# GD32A72_A74x register map
File version: 1.0
CPU: CM7 r2p1, little endian, MPU, FPU, DSP, 4 interrupt priority bits
Registers are 32-bit, read-write, reset 0x0 unless marked. A register's access mark holds for its fields unless they carry their own. Offsets are from the block's base; [hi:lo] are bit positions; {n}, {i} and the like mark numbered series; 'fields as' and 'values as' point back to an identical list.

## SYSCFG — System and memory architecture
Base 0x40010000
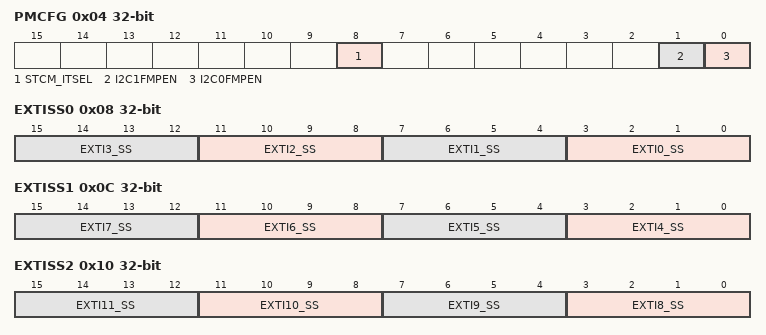
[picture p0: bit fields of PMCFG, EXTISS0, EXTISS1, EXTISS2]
0x04 PMCFG — Peripheral mode configuration register
  [8] STCM_ITSEL — STCM server interface selection
  [1] I2C1FMPEN — I2C1 Fm+
  [0] I2C0FMPEN — I2C0 Fm+
0x08 EXTISS0 — EXTI sources selection register 0
  [4n+3:4n] EXTI{n}_SS (n=0..3) — EXTI {n} sources selection
0x0C EXTISS1 — EXTI sources selection register 1
  [4n-13:4n-16] EXTI{n}_SS (n=4..7) — EXTI {n} sources selection
0x10 EXTISS2 — EXTI sources selection register 2
  [4n-29:4n-32] EXTI{n}_SS (n=8..11) — EXTI {n} sources selection
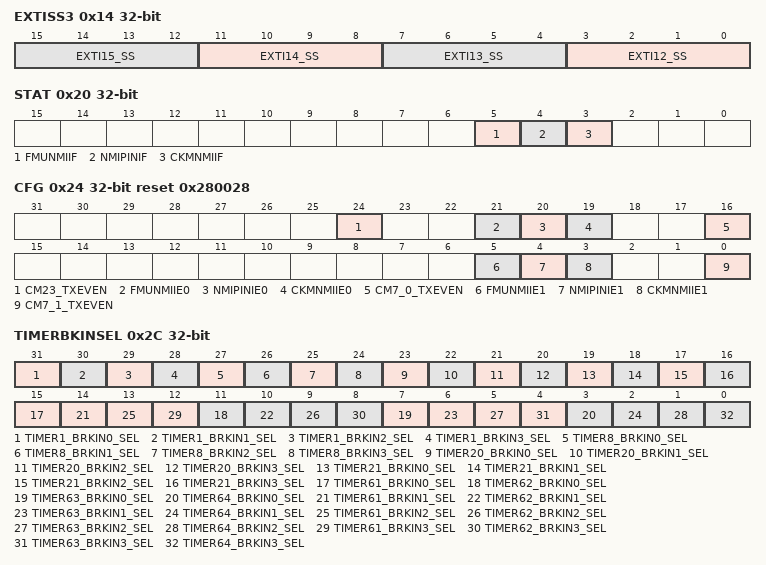
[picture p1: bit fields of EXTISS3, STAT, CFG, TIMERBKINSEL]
0x14 EXTISS3 — EXTI sources selection register 3
  [4n-45:4n-48] EXTI{n}_SS (n=12..15) — EXTI {n} sources selection
0x20 STAT access per field — System status register
  [5] FMUNMIIF ro — NMI interrupt flag from FMU
  [4] NMIPINIF ro — NMI interrupt flag from EXTI pin
  [3] CKMNMIIF rw — HXTAL clock monitor NMI interrupt flag
0x24 CFG reset 0x280028 — System configuration register
  [24] CM23_TXEVEN — This bit can be used to enable the EVENTOUT from CM23
  [21] FMUNMIIE0 — This bit can be used to enable the interrupt flag from FMU connection to CPU0 NMI interrupt
  [20] NMIPINIE0 — This bit can be used to enable the interrupt flag from EXTI connection to CPU0 NMI interrupt
  [19] CKMNMIIE0 — This bit can be used to enable the HXTAL clock monitor NMI interrupt flag connection to CPU0 NMI interrupt
  [16] CM7_0_TXEVEN — This bit can be used to enable the EVENTOUT from CM7_0
  [5] FMUNMIIE1 — This bit can be used to enable the interrupt flag from FMU connection to CPU1 NMI interrupt
  [4] NMIPINIE1 — This bit can be used to enable the interrupt flag from EXTI connection to CPU1 NMI interrupt
  [3] CKMNMIIE1 — This bit can be used to enable the HXTAL clock monitor NMI interrupt flag connection to CPU1 NMI interrupt
  [0] CM7_1_TXEVEN — This bit can be used to enable the EVENTOUT from CM7_1
0x2C TIMERBKINSEL — Timer break input select register
  [31] TIMER1_BRKIN0_SEL — Timer1 break input 3 select
  [30] TIMER1_BRKIN1_SEL — Timer1 break input 2 select
  [29] TIMER1_BRKIN2_SEL — Timer1 break input 1 select
  [28] TIMER1_BRKIN3_SEL — Timer1 break input 0 select
  [27] TIMER8_BRKIN0_SEL — Timer8 break input 3 select
  [26] TIMER8_BRKIN1_SEL — Timer8 break input 2 select
  [25] TIMER8_BRKIN2_SEL — Timer8 break input 1 select
  [24] TIMER8_BRKIN3_SEL — Timer8 break input 0 select
  [23] TIMER20_BRKIN0_SEL — Timer20 break input 3 select
  [22] TIMER20_BRKIN1_SEL — Timer20 break input 2 select
  [21] TIMER20_BRKIN2_SEL — Timer20 break input 1 select
  [20] TIMER20_BRKIN3_SEL — Timer20 break input 0 select
  [19] TIMER21_BRKIN0_SEL — Timer21 break input 3 select
  [18] TIMER21_BRKIN1_SEL — Timer21 break input 2 select
  [17] TIMER21_BRKIN2_SEL — Timer21 break input 1 select
  [16] TIMER21_BRKIN3_SEL — Timer21 break input 0 select
  [259-4n] TIMER{n}_BRKIN0_SEL (n=61..64) — Timer{n} break input 3 select
  [258-4n] TIMER{n}_BRKIN1_SEL (n=61..64) — Timer{n} break input 2 select
  [257-4n] TIMER{n}_BRKIN2_SEL (n=61..64) — Timer{n} break input 1 select
  [256-4n] TIMER{n}_BRKIN3_SEL (n=61..64) — Timer{n} break input 0 select
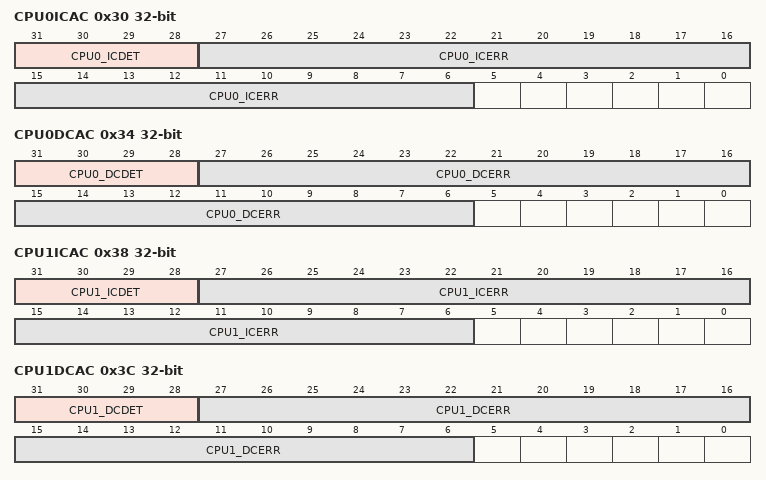
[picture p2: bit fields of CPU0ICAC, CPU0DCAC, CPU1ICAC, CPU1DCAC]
0x30 CPU0ICAC ro — CPU0 ICACHE error status register
  [31:28] CPU0_ICDET — The icache error detection information
  [27:6] CPU0_ICERR — The icache error bank information
0x34 CPU0DCAC ro — CPU0 DCACHE error status register
  [31:28] CPU0_DCDET — The dcache error detection information
  [27:6] CPU0_DCERR — The dcache error bank information
0x38 CPU1ICAC ro — CPU1 ICACHE error status register
  [31:28] CPU1_ICDET — The icache error detection information
  [27:6] CPU1_ICERR — The icache error bank information
0x3C CPU1DCAC ro — CPU1 DCACHE error status register
  [31:28] CPU1_DCDET — The dcache error detection information
  [27:6] CPU1_DCERR — The dcache error bank information
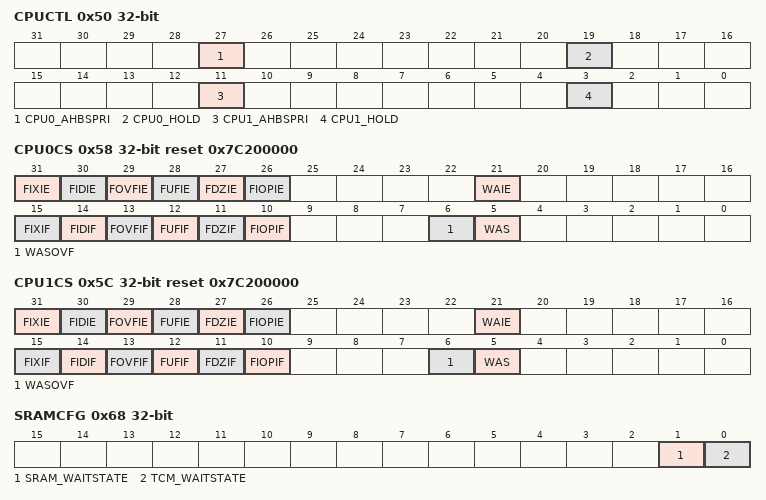
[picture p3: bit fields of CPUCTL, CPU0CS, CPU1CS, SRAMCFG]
0x50 CPUCTL — CPU control register
  [27] CPU0_AHBSPRI — AHB slave port priority of the CM7_0
  [19] CPU0_HOLD — CPU0 hold released
  [11] CPU1_AHBSPRI — AHB slave priority of the CM7_1
  [3] CPU1_HOLD — CPU1 hold released
0x54 CPUSTAT — CPU platform status register
  [1:0] CPUSTAT — CPU information for the chip
0x58 CPU0CS access per field reset 0x7C200000 — CPU0 control and status register
  [31] FIXIE rw — FPU inexact interrupt enable
  [30] FIDIE rw — FPU input denormal interrupt enable
  [29] FOVFIE rw — FPU overflow interrupt enable
  [28] FUFIE rw — FPU underflow interrupt enable
  [27] FDZIE rw — FPU divide-by-zero interrupt enable
  [26] FIOPIE rw — FPU invalid operation interrupt enable
  [21] WAIE rw — TCM write abort interrupt enable
  [15] FIXIF ro — FPU inexact interrupt flag status
  [14] FIDIF ro — FPU input denormal interrupt flag status
  [13] FOVFIF ro — FPU overflow interrupt flag status
  [12] FUFIF ro — FPU underflow interrupt flag status
  [11] FDZIF ro — FPU divide-by-zero interrupt flag status
  [10] FIOPIF ro — FPU invalid operation interrupt flag status
  [6] WASOVF ro — Write abort on slave overrun flag
  [5] WAS rw — Write abort on AHB slave
0x5C CPU1CS access per field reset 0x7C200000 — CPU1 control and status register
  fields as CPU0CS
0x68 SRAMCFG — SRAM configuration register
  [1] SRAM_WAITSTATE — This bit is set and cleared by software
  [0] TCM_WAITSTATE — This bit is set and cleared by software
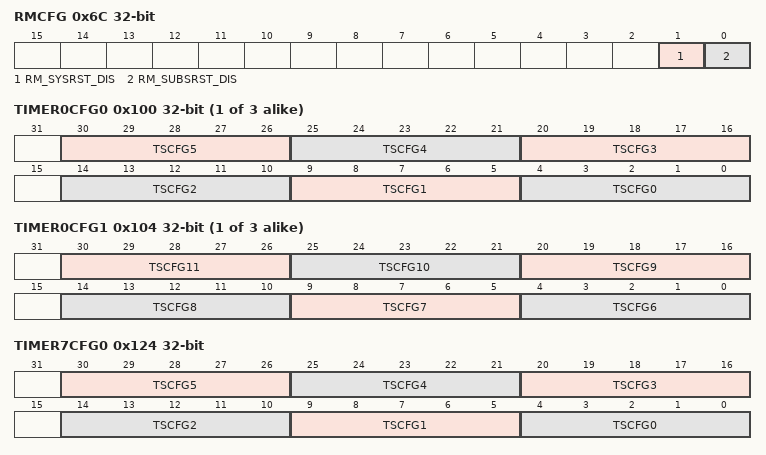
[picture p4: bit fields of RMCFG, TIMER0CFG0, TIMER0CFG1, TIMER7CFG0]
0x6C RMCFG — Recovery mode configuration register
  [1] RM_SYSRST_DIS — Disable recovery mode on system reset
  [0] RM_SUBSRST_DIS — Disable recovery mode on subsystem reset
0x70 HSMSTAT — HSM sub system status register
  [0] HSM_ENTER_STDBY — Indicates that the HSM sub system has entered standby separately
{0x100+0xC*i} TIMER{i}CFG0 (i=0..2) — TIMER{i} configuration register 0
  [30:26] TSCFG5 — Event mode configuration
  [25:21] TSCFG4 — Pause mode configuration
  [20:16] TSCFG3 — Restart mode configuration
  [14:10] TSCFG2 — Quadrature decoder mode 2 configuration
  [9:5] TSCFG1 — Quadrature decoder mode 1 configuration
  [4:0] TSCFG0 — Quadrature decoder mode 0 configuration
{0x104+0xC*i} TIMER{i}CFG1 (i=0..2) — TIMER{i} configuration register 1
  [30:26] TSCFG11 — Non-quadrature decoder mode 3 configuration
  [25:21] TSCFG10 — Non-quadrature decoder mode 2 configuration
  [20:16] TSCFG9 — Non-quadrature decoder mode 1 configuration
  [14:10] TSCFG8 — Non-quadrature decoder mode 0 configuration
  [9:5] TSCFG7 — Restart + event mode configuration
  [4:0] TSCFG6 — External clock mode 0 configuration
{0x108+0xC*i} TIMER{i}CFG2 (i=0..2) — TIMER{i} configuration register 2
  [20:16] TSCFG15 — Internal trigger input source configuration
0x124 TIMER7CFG0 — TIMER7 configuration register 0
  fields as TIMER0CFG0
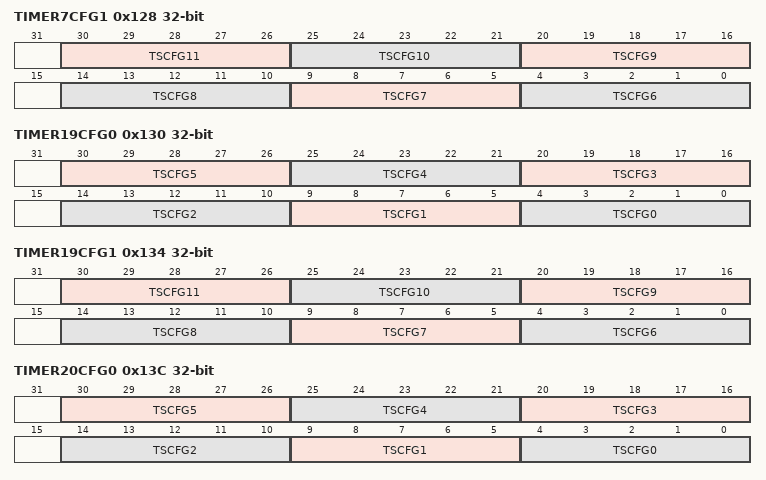
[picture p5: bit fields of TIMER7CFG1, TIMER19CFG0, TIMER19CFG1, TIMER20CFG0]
0x128 TIMER7CFG1 — TIMER7 configuration register 1
  fields as TIMER0CFG1
0x12C TIMER7CFG2 — TIMER7 configuration register 2
  [20:16] TSCFG15 — Internal trigger input source configuration
0x130 TIMER19CFG0 — TIMER19 configuration register 0
  fields as TIMER0CFG0
0x134 TIMER19CFG1 — TIMER19 configuration register 1
  fields as TIMER0CFG1
0x138 TIMER19CFG2 — TIMER19 configuration register 2
  [20:16] TSCFG15 — Internal trigger input source configuration
0x13C TIMER20CFG0 — TIMER20 configuration register 0
  fields as TIMER0CFG0
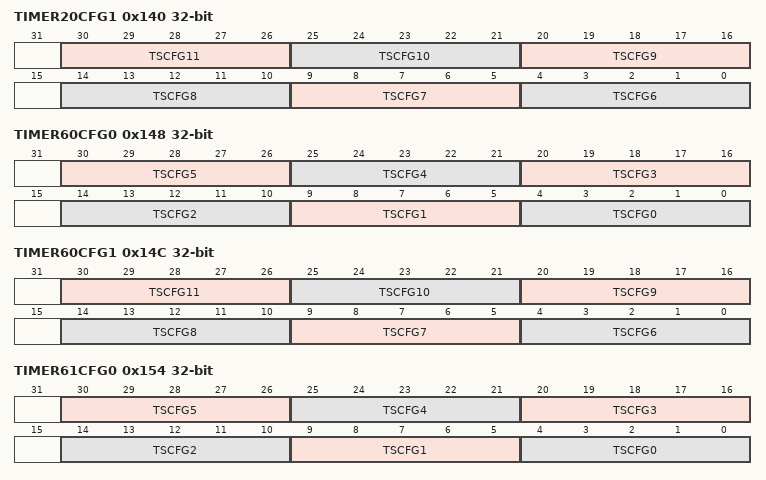
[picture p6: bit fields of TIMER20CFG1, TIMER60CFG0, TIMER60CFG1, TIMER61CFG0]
0x140 TIMER20CFG1 — TIMER20 configuration register 1
  fields as TIMER0CFG1
0x144 TIMER20CFG2 — TIMER20 configuration register 2
  [20:16] TSCFG15 — Internal trigger input source configuration
0x148 TIMER60CFG0 — TIMER60 configuration register 0
  fields as TIMER0CFG0
0x14C TIMER60CFG1 — TIMER60 configuration register 1
  fields as TIMER0CFG1
0x150 TIMER60CFG2 — TIMER60 configuration register 2
  [20:16] TSCFG15 — Internal trigger input source configuration
0x154 TIMER61CFG0 — TIMER61 configuration register 0
  fields as TIMER0CFG0
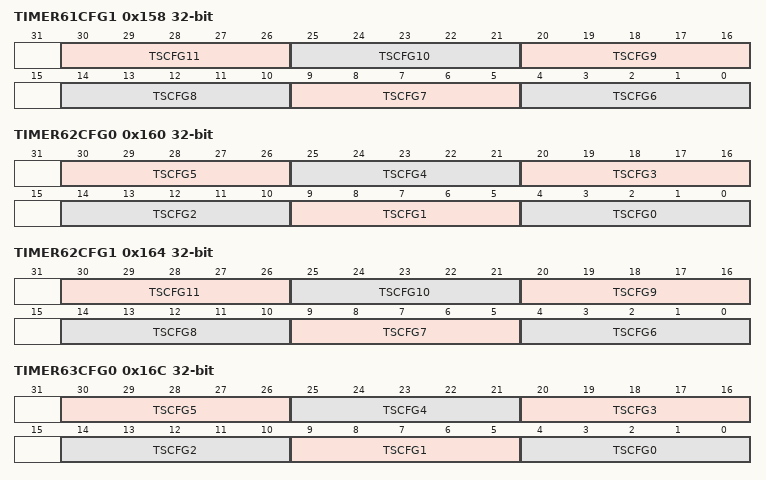
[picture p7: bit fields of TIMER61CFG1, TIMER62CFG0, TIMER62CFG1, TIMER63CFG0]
0x158 TIMER61CFG1 — TIMER61 configuration register 1
  fields as TIMER0CFG1
0x15C TIMER61CFG2 — TIMER61 configuration register 2
  [20:16] TSCFG15 — Internal trigger input source configuration
0x160 TIMER62CFG0 — TIMER62 configuration register 0
  fields as TIMER0CFG0
0x164 TIMER62CFG1 — TIMER62 configuration register 1
  fields as TIMER0CFG1
0x168 TIMER62CFG2 — TIMER62 configuration register 2
  [20:16] TSCFG15 — Internal trigger input source configuration
0x16C TIMER63CFG0 — TIMER63 configuration register 0
  fields as TIMER0CFG0
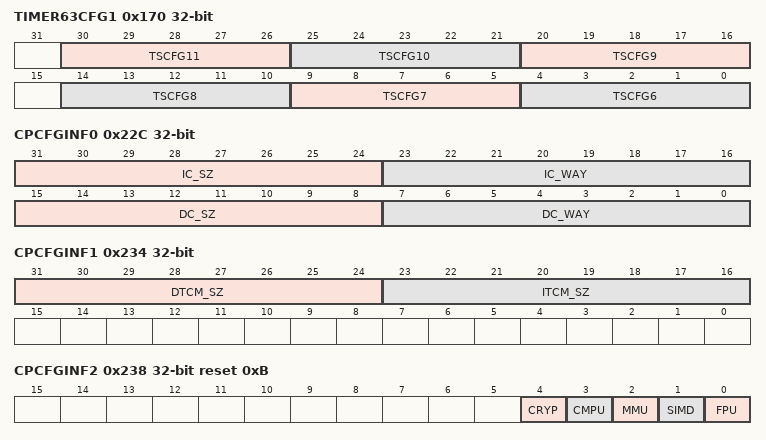
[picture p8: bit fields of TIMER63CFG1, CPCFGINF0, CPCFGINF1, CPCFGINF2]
0x170 TIMER63CFG1 — TIMER63 configuration register 1
  fields as TIMER0CFG1
0x174 TIMER63CFG2 — TIMER63 configuration register 2
  [20:16] TSCFG15 — Internal trigger input source configuration
0x220 CPID ro — Core processor ID register
  [31:0] CPID — Core processor ID
0x224 CPNUM ro — Core porcessor number register
  [1:0] CPNUM — CPU core number
0x22C CPCFGINF0 ro — Core processor configuration information register 0
  [31:24] IC_SZ — L1 instruction cache size
  [23:16] IC_WAY — L1 instruction cache ways
  [15:8] DC_SZ — L1 data cache size
  [7:0] DC_WAY — L1 data cache ways
0x234 CPCFGINF1 ro — Core processor configuration information register 1
  [31:24] DTCM_SZ — DTCM memory size
  [23:16] ITCM_SZ — ITCM memory size
0x238 CPCFGINF2 ro reset 0xB — Core processor configuration information register 2
  [4] CRYP — Cryptography support
  [3] CMPU — Core memory protection unit support
  [2] MMU — Memory management unit support
  [1] SIMD — SIMD/NEON instruction support
  [0] FPU — Floating point unit support
0x240 CP0ID ro reset 0x434D3730 — Core processor 0 ID register
  [31:0] CPID — Core processor ID
0x244 CP0NUM ro — Core processor 0 number register
  [1:0] CPNUM — CPU core number
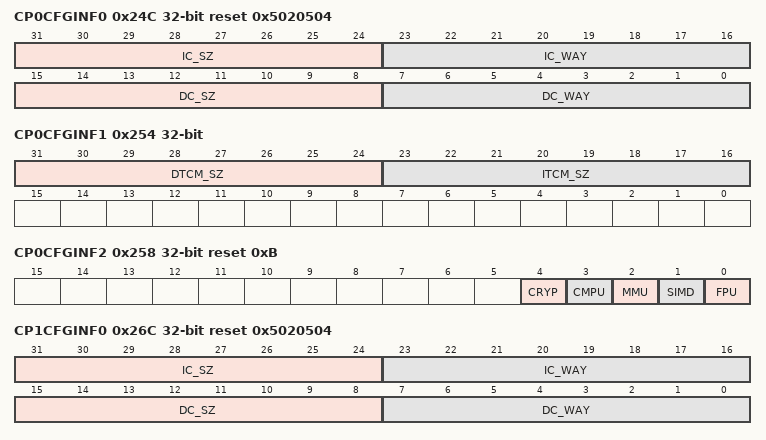
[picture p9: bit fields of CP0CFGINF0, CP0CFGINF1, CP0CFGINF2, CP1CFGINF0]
0x24C CP0CFGINF0 ro reset 0x5020504 — Core processor 0 configuration information register 0
  fields as CPCFGINF0
0x254 CP0CFGINF1 ro — Core processor 0 configuration information register 1
  fields as CPCFGINF1
0x258 CP0CFGINF2 ro reset 0xB — Core processor 0 configuration information register 2
  fields as CPCFGINF2
0x260 CP1ID ro reset 0x434D3731 — Core processor 1 ID register
  [31:0] CPID — Core processor ID
0x264 CP1NUM ro reset 0x1 — Core processor 1 number register
  [1:0] CPNUM — CPU core number
0x26C CP1CFGINF0 ro reset 0x5020504 — Core processor 1 configuration information register 0
  fields as CPCFGINF0
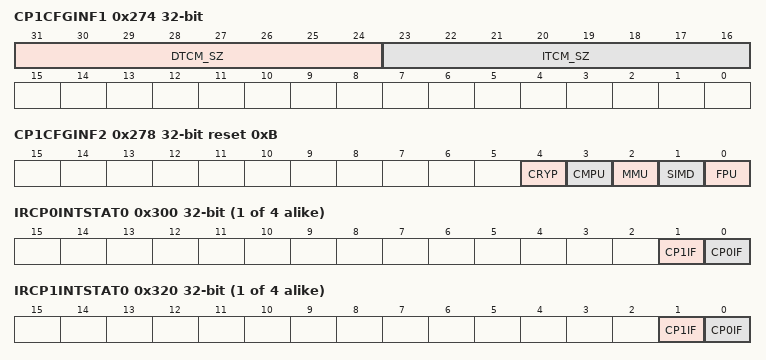
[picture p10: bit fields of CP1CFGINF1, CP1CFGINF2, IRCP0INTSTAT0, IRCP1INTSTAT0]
0x274 CP1CFGINF1 ro — Core processor 1 configuration information register 1
  fields as CPCFGINF1
0x278 CP1CFGINF2 ro reset 0xB — Core processor 1 configuration information register 2
  fields as CPCFGINF2
{0x300+8i} IRCP0INTSTAT{i} (i=0..3) — Interrupt router core processor 0 interrupt status register x
  [1] CP1IF — CP1 to CP0 interrupt flag
  [0] CP0IF — CP0 to CP0 interrupt flag
{0x304+8i} IRCP0INT{i} wo (i=0..3) — Interrupt router core processor 0 interrupt register x
  [0] CPIE — Interrupt enable
{0x320+8i} IRCP1INTSTAT{i} (i=0..3) — Interrupt router core processor 1 interrupt status register x
  [1] CP1IF — CP1-to-CP1 interrupt flag
  [0] CP0IF — CP0-to-CP1 interrupt flag
{0x324+8i} IRCP1INT{i} wo (i=0..3) — Interrupt router core processor 1 interrupt register x
  [0] CPIE — Interrupt enable
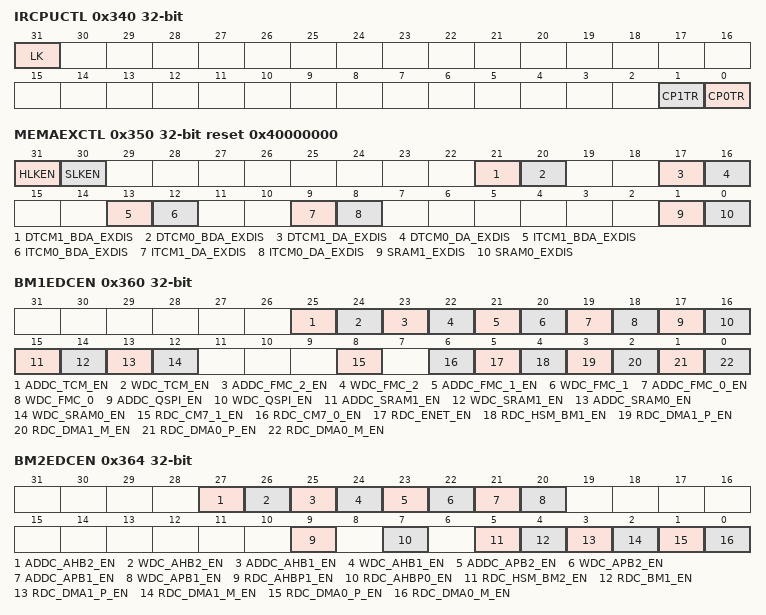
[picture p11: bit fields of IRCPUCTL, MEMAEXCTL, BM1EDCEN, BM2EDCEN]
0x340 IRCPUCTL — Interrupt router core processor control register
  [31] LK — Lock bit
  [1] CP1TR — CP1 configured as trusted core
  [0] CP0TR — CP0 configured as trusted core
0x350 MEMAEXCTL reset 0x40000000 — Memory access execution control registerDTCM0_ DA_EXDIS
  [31] HLKEN — Hard lock enable
  [30] SLKEN — Soft lock enable
  [21] DTCM1_BDA_EXDIS — DTCM core 1 backdoor access execution control
  [20] DTCM0_BDA_EXDIS — DTCM core 0 backdoor access execution control
  [17] DTCM1_DA_EXDIS — DTCM core 1 direct access execution control
  [16] DTCM0_DA_EXDIS — DTCM core 0 direct access execution control
  [13] ITCM1_BDA_EXDIS — ITCM core 1 backdoor access execution control
  [12] ITCM0_BDA_EXDIS — ITCM core 0 backdoor access execution control
  [9] ITCM1_DA_EXDIS — ITCM core 1 direct access execution control
  [8] ITCM0_DA_EXDIS — ITCM core 0 direct access execution control
  [1] SRAM1_EXDIS — SRAM 1 controller access execution control
  [0] SRAM0_EXDIS — SRAM 0 controller access execution control
0x360 BM1EDCEN — Bus matrix 1 interconnect error detection enable register
  [25] ADDC_TCM_EN — Address check TCM SRAM enable
  [24] WDC_TCM_EN — Write data check TCM SRAM enable
  [23] ADDC_FMC_2_EN — Enable address check FMC_2
  [22] WDC_FMC_2 — Enable write data check FMC_2
  [21] ADDC_FMC_1_EN — Enable address check FMC_1
  [20] WDC_FMC_1 — Enable write data check FMC_1
  [19] ADDC_FMC_0_EN — Enable address check FMC_0
  [18] WDC_FMC_0 — Enable write data check FMC_0
  [17] ADDC_QSPI_EN — Enable address check Quad-SPI
  [16] WDC_QSPI_EN — Enable write data check Quad-SPI
  [15] ADDC_SRAM1_EN — Enable address check SRAM1
  [14] WDC_SRAM1_EN — Enable write data check SRAM1
  [13] ADDC_SRAM0_EN — Enable address check SRAM0
  [12] WDC_SRAM0_EN — Enable write data check SRAM0
  [8] RDC_CM7_1_EN — Enable read data check Cortex-M7_1_AXIM
  [6] RDC_CM7_0_EN — Enable read data check Cortex-M7_0_AXIM
  [5] RDC_ENET_EN — Enable read data check ENET
  [4] RDC_HSM_BM1_EN — Enable read data check HSM BM1
  [3] RDC_DMA1_P_EN — Enable read data check DMA1 peripheral accesses
  [2] RDC_DMA1_M_EN — Enable read data check DMA1 memory accesses
  [1] RDC_DMA0_P_EN — Enable read data check DMA0 peripheral accesses
  [0] RDC_DMA0_M_EN — Enable read data check DMA0 memory accesses
0x364 BM2EDCEN — Bus matrix 2 interconnect error detection enable register
  [27] ADDC_AHB2_EN — Enable address check AHB2
  [26] WDC_AHB2_EN — Enable write data check AHB2
  [25] ADDC_AHB1_EN — Enable address check AHB1
  [24] WDC_AHB1_EN — Enable write data check AHB1
  [23] ADDC_APB2_EN — Enable address check APB2
  [22] WDC_APB2_EN — Enable write data check APB2
  [21] ADDC_APB1_EN — Enable address check APB1
  [20] WDC_APB1_EN — Enable write data check APB1
  [9] RDC_AHBP1_EN — Enable read data check Cortex-M7_1_AHBP
  [7] RDC_AHBP0_EN — Enable read data check Cortex-M7_0_AHBP
  [5] RDC_HSM_BM2_EN — Enable read data check HSM BM2
  [4] RDC_BM1_EN — Enable read data check Bus Matrix2 to Bus Matrix1
  [3] RDC_DMA1_P_EN — Enable read data check DMA1 peripheral accesses
  [2] RDC_DMA1_M_EN — Enable read data check DMA1 memory accesses
  [1] RDC_DMA0_P_EN — Enable read data check DMA0 peripheral accesses
  [0] RDC_DMA0_M_EN — Enable read data check DMA0 memory accesses
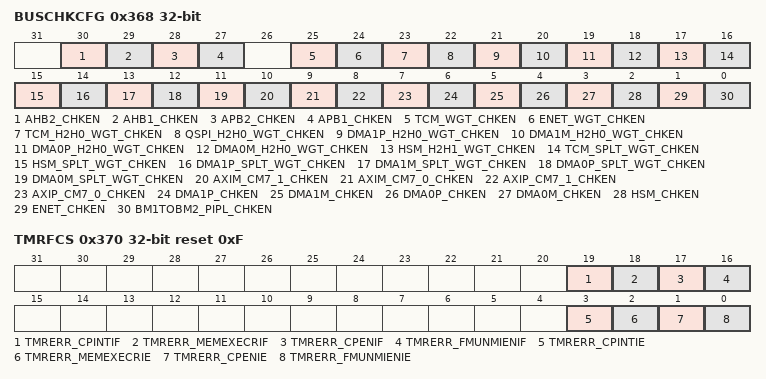
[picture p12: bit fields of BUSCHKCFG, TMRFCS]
0x368 BUSCHKCFG — Bus check configuration register
  [30] AHB2_CHKEN — Enable or disable AHB2 redundant check
  [29] AHB1_CHKEN — Enable or disable AHB1 redundant check
  [28] APB2_CHKEN — Enable or disable APB2 redundant check
  [27] APB1_CHKEN — Enable or disable APB1 redundant check
  [25] TCM_WGT_CHKEN — Enable or disable TCM 1:1 widget check
  [24] ENET_WGT_CHKEN — Enable or disable ENET 1:1/1:2 widget check
  [23] TCM_H2H0_WGT_CHKEN — Enable or disable H2H0 widget of TCM redundant check
  [22] QSPI_H2H0_WGT_CHKEN — Enable or disable H2H0 widget of QSPI redundant check
  [21] DMA1P_H2H0_WGT_CHKEN — Enable or disable H2H0 widget of DMA1 peri redundant check
  [20] DMA1M_H2H0_WGT_CHKEN — Enable or disable H2H0 widget of DMA1 mem redundant check
  [19] DMA0P_H2H0_WGT_CHKEN — Enable or disable H2H0 widget of DMA0 peri redundant check
  [18] DMA0M_H2H0_WGT_CHKEN — Enable or disable H2H0 widget of DMA0 mem redundant check
  [17] HSM_H2H1_WGT_CHKEN — Enable or disable H2H1 widget of HSM redundant check
  [16] TCM_SPLT_WGT_CHKEN — Enable or disable Split1 widget of TCM SRAM redundant check
  [15] HSM_SPLT_WGT_CHKEN — Enable or disable Split1 widget of HSM redundant check
  [14] DMA1P_SPLT_WGT_CHKEN — Enable or disable Split0 widget of DMA1 peri redundant check
  [13] DMA1M_SPLT_WGT_CHKEN — Enable or disable Split0 widget of DMA1 mem redundant check
  [12] DMA0P_SPLT_WGT_CHKEN — Enable or disable Split0 widget of DMA0 peri redundant check
  [11] DMA0M_SPLT_WGT_CHKEN — Enable or disable Split0 widget of DMA0 mem redundant check
  [10] AXIM_CM7_1_CHKEN — Enable or disable CM7_1 AXIM port timeout and slaver ID check
  [9] AXIM_CM7_0_CHKEN — Enable or disable CM7_0 AXIM port timeout and slaver ID check
  [8] AXIP_CM7_1_CHKEN — Enable or disable CM7_1 AHBP port timeout and slaver ID check
  [7] AXIP_CM7_0_CHKEN — Enable or disable CM7_0 AHBP port timeout and slaver ID check
  [6] DMA1P_CHKEN — Enable or disable DMA1 peri port timeout and slaver ID check
  [5] DMA1M_CHKEN — Enable or disable DMA1 mem port timeout and slaver ID check
  [4] DMA0P_CHKEN — Enable or disable DMA0 peri port timeout and slaver ID check
  [3] DMA0M_CHKEN — Enable or disable DMA0 mem port timeout and slaver ID check
  [2] HSM_CHKEN — Enable or disable HSM port timeout and slaver ID check
  [1] ENET_CHKEN — Enable or disable ENET mem port timeout and slaver ID check
  [0] BM1TOBM2_PIPL_CHKEN — Enable or disable BM1 to BM2 pipeline check
0x370 TMRFCS reset 0xF — TMR fault control and status register
  [19] TMRERR_CPINTIF — TMR fault interrupt flag of the interrupt router CPn interrupt status registers
  [18] TMRERR_MEMEXECRIF — TMR fault interrupt flag of the memory access execution control register
  [17] TMRERR_CPENIF — TMR fault interrupt flag of the CPU (CPU0/CPU1) released enable
  [16] TMRERR_FMUNMIENIF — TMR fault interrupt flag of the FMU NMI interrupt flag enable
  [3] TMRERR_CPINTIE — TMR fault interrupt enable of the interrupt router CPn interrupt status registers
  [2] TMRERR_MEMEXECRIE — TMR fault interrupt enable of the memory access execution control register
  [1] TMRERR_CPENIE — TMR fault interrupt enable of the CPU (CPU0/CPU1) released
  [0] TMRERR_FMUNMIENIE — TMR fault interrupt enable of the FMU NMI interrupt flag enable
